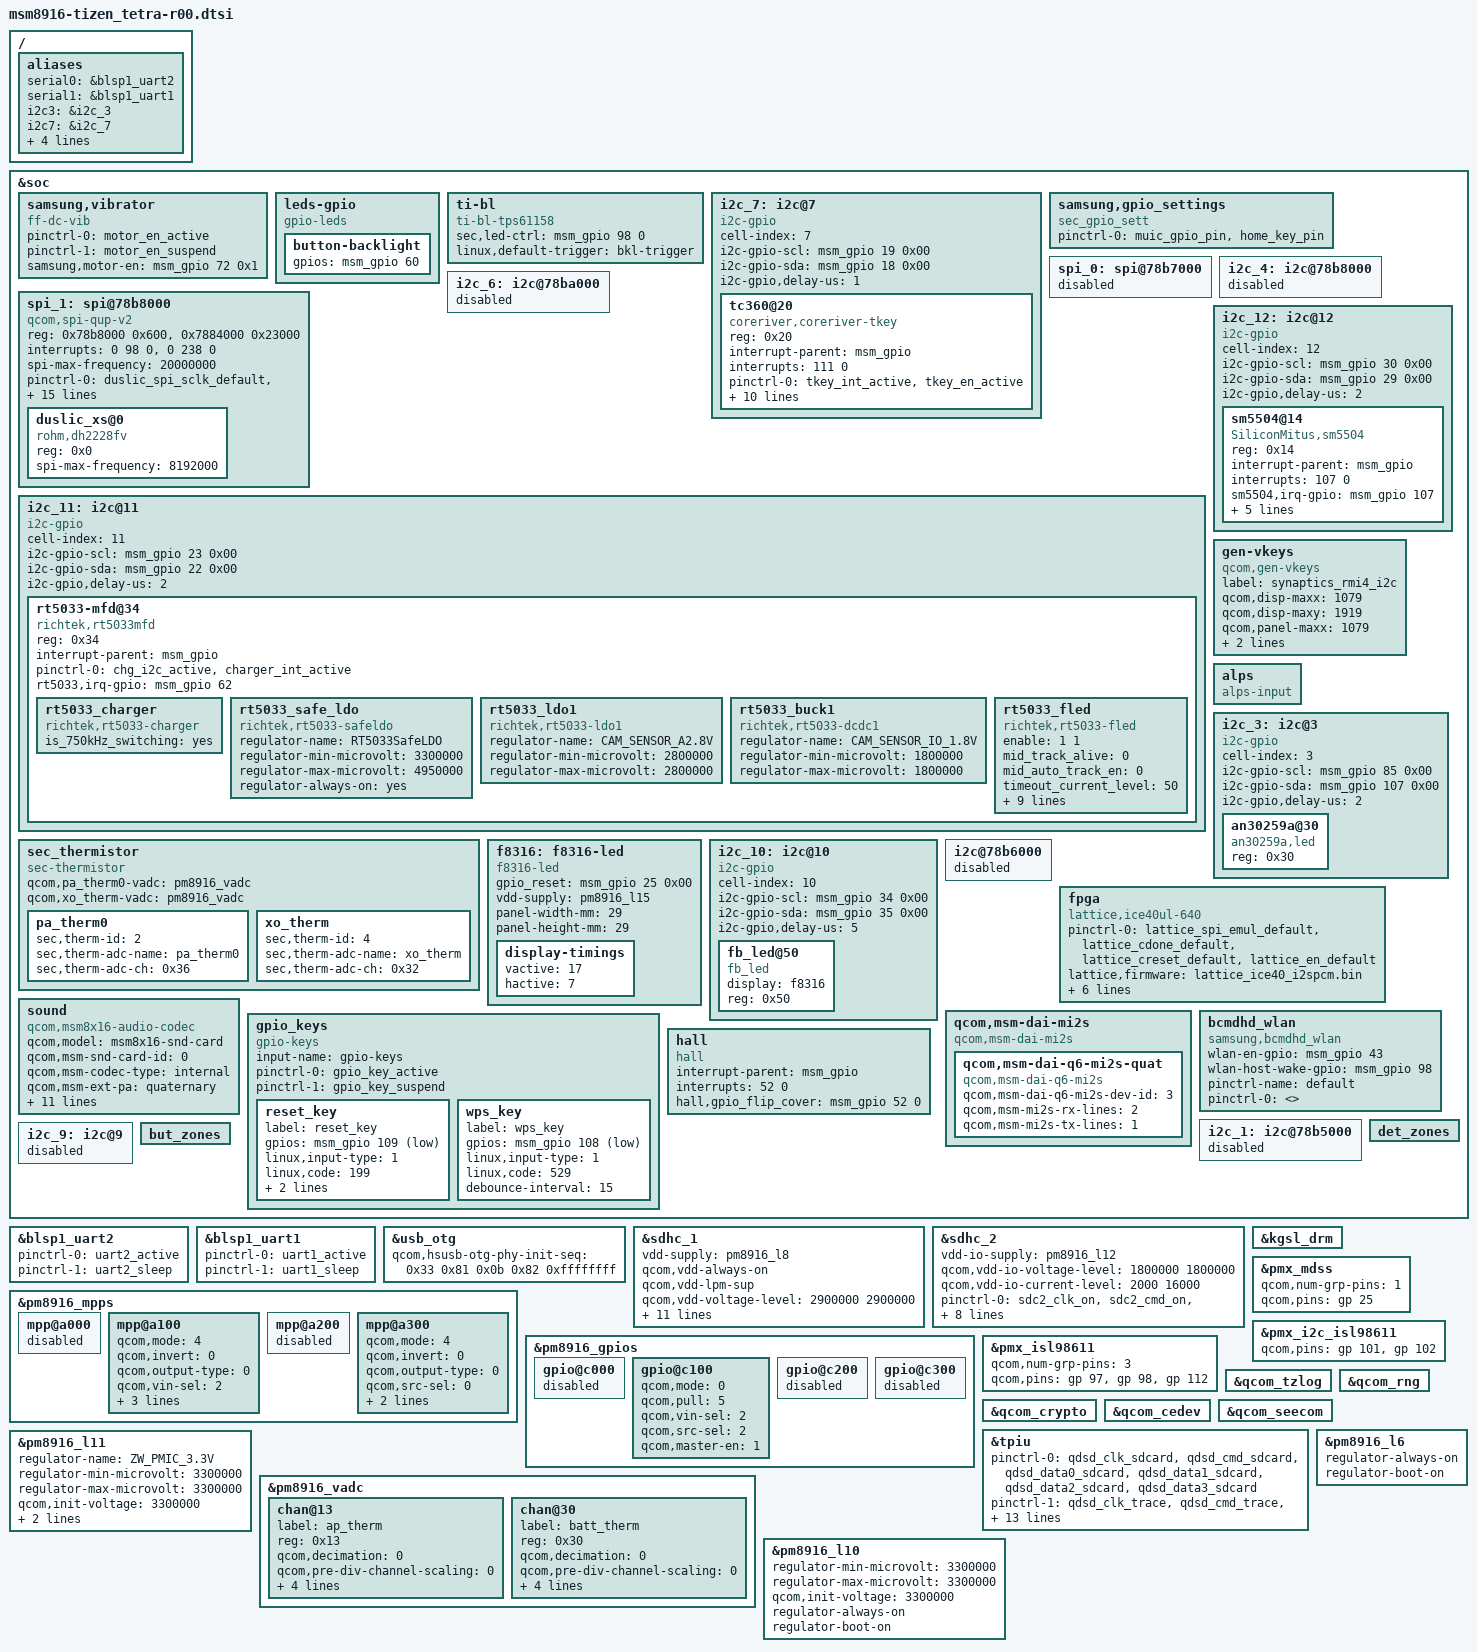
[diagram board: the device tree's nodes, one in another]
/* Copyright (c) 2014, The Linux Foundation. All rights reserved.
 *
 * This program is free software; you can redistribute it and/or modify
 * it under the terms of the GNU General Public License version 2 and
 * only version 2 as published by the Free Software Foundation.
 *
 * This program is distributed in the hope that it will be useful,
 * but WITHOUT ANY WARRANTY; without even the implied warranty of
 * MERCHANTABILITY or FITNESS FOR A PARTICULAR PURPOSE.  See the
 * GNU General Public License for more details.
 */

#include "msm8916.dtsi"
#include "msm8916-pinctrl-tizen-tetra-r00.dtsi"
#include "msm8916-w1-r01.dtsi"

/ {
	aliases {
		serial0 = &blsp1_uart2;
		serial1 = &blsp1_uart1;

		/*i2c-gpio bus_id*/
		i2c3 = &i2c_3;
		i2c7 = &i2c_7;
		i2c11 = &i2c_11;
		i2c12 = &i2c_12;
		i2c10 = &i2c_10;
		/*spi-gpio bus_id*/
		spi1 = &spi_1;
		};
};

&soc {
	samsung,vibrator {
		pinctrl-names = "tlmm_motor_en_active","tlmm_motor_en_suspend";
		pinctrl-0 = <&motor_en_active>;
		pinctrl-1 = <&motor_en_suspend>;
		compatible = "ff-dc-vib";
		samsung,motor-en = <&msm_gpio 72 0x1>;
		status = "ok";
	};

	leds-gpio{
		compatible = "gpio-leds";
		button-backlight{
			gpios = <&msm_gpio 60 0>;
			status = "ok";
		};
	};

	ti-bl {
		compatible = "ti-bl-tps61158";
		sec,led-ctrl = <&msm_gpio 98 0>;
		linux,default-trigger = "bkl-trigger";
	};

	i2c_7:i2c@7 {
                cell-index = <7>;
                compatible = "i2c-gpio";
                i2c-gpio-scl = <&msm_gpio 19  0x00>;
                i2c-gpio-sda = <&msm_gpio 18 0x00>;
                i2c-gpio,delay-us = <1>;
                #address-cells = <1>;
                #size-cells = <0>;

                tc360@20 {
                        compatible = "coreriver,coreriver-tkey";
                        reg = <0x20>;
                        interrupt-parent = <&msm_gpio>;
                        interrupts = <111 0>;
		pinctrl-names = "tkey_gpio_active","tkey_gpio_suspend";
		pinctrl-0 = <&tkey_int_active &tkey_en_active>;
		pinctrl-1 = <&tkey_int_suspend &tkey_en_suspend>;
                        coreriver,vcc_en-gpio = <&msm_gpio 60 0x00>;
                        coreriver,scl-gpio = <&msm_gpio 19 0x00>;
                        coreriver,sda-gpio = <&msm_gpio 18 0x00>;
                        coreriver,irq-gpio = <&msm_gpio  111 0x00>;
                        coreriver,keycodes = <169 158 529>;
                        coreriver,i2c-pull-up = <1>;
                        coreriver,gpio_seperated = <1>;
                        coreriver,fw-name = "tc350_tetra";
                        coreriver,firm-up;
                };
        };

	samsung,gpio_settings{
		compatible = "sec_gpio_sett";
		pinctrl-names = "sec_gpio_active","sec_gpio_suspend";
		pinctrl-0 = <&muic_gpio_pin &home_key_pin>;
	};

	spi_0: spi@78b7000 { /* BLSP1 QUP2 */
		status = "disable";
	};

	i2c_4: i2c@78b8000 { /* BLSP1 QUP4 */
		status = "disable";
	};

	spi_1: spi@78b8000 { /* BLSP1 QUP3 */
		compatible = "qcom,spi-qup-v2";
		#address-cells = <1>;
		#size-cells = <0>;
		reg-names = "spi_physical", "spi_bam_physical";
		reg = <0x78b8000 0x600>, <0x7884000 0x23000>;
		interrupt-names = "spi_irq", "spi_bam_irq";
		interrupts = <0 98 0>, <0 238 0>;
		spi-max-frequency = <20000000>;

		pinctrl-names = "default", "sleep";
		pinctrl-0 = <&duslic_spi_sclk_default &duslic_spi_mosi_default &duslic_spi_miso_default &duslic_spi_cs_default>;
		pinctrl-1 = <&duslic_spi_sclk_sleep &duslic_spi_mosi_sleep &duslic_spi_miso_sleep &duslic_spi_cs_sleep>;

		clock-names = "iface_clk", "core_clk";
		clocks = <&clock_gcc clk_gcc_blsp1_ahb_clk>, <&clock_gcc clk_gcc_blsp1_qup4_spi_apps_clk>;
		qcom,infinite-mode = <0>;
		qcom,use-bam;
		qcom,use-pinctrl;
		qcom,ver-reg-exists;
		qcom,bam-consumer-pipe-index = <10>;
		qcom,bam-producer-pipe-index = <11>;
		qcom,master-id = <86>;
		status = "ok";

		duslic_xs@0 {
		    compatible = "rohm,dh2228fv";
		    reg = <0x0>;
		    spi-max-frequency = <8192000>;
		};
	};

	i2c_6: i2c@78ba000 { /* BLSP1 QUP6 */
		status = "disable";
	};

       i2c_11:i2c@11 {
		cell-index = <11>;
		compatible = "i2c-gpio";
		i2c-gpio-scl = <&msm_gpio 23 0x00>;
		i2c-gpio-sda = <&msm_gpio 22 0x00>;
		i2c-gpio,delay-us = <2>;
		#address-cells = <1>;
		#size-cells = <0>;

		rt5033-mfd@34{
			compatible = "richtek,rt5033mfd";
			reg = <0x34>;
			interrupt-parent = <&msm_gpio>;
			pinctrl-names = "default";
			pinctrl-0 = <&chg_i2c_active &charger_int_active>;
			rt5033,irq-gpio = <&msm_gpio 62 0x00>;

			rt5033_charger {
				compatible = "richtek,rt5033-charger";
				is_750kHz_switching = "yes";
			};

			rt5033_safe_ldo {
				compatible = "richtek,rt5033-safeldo";
				regulator-name = "RT5033SafeLDO"; /* constraints->name, change name by yourself*/
				regulator-min-microvolt = <3300000>;
				regulator-max-microvolt = <4950000>; /* if max == min then apply_uV = 1 */
				regulator-always-on = "yes";
			};

			rt5033_ldo1 {
				compatible = "richtek,rt5033-ldo1";
				regulator-name = "CAM_SENSOR_A2.8V"; /* change name by yourself */
				regulator-min-microvolt = <2800000>;
				regulator-max-microvolt = <2800000>; /* max == min then apply_uV = 1 */
			};


			rt5033_buck1 {
				compatible = "richtek,rt5033-dcdc1";
				regulator-name = "CAM_SENSOR_IO_1.8V"; /* change name by yourself */
				regulator-min-microvolt = <1800000>;
				regulator-max-microvolt = <1800000>; /* max == min then apply_uV = 1 */
			};

			rt5033_fled {
				compatible = "richtek,rt5033-fled";
				enable = <1 1>;
				mid_track_alive = <0>;
				mid_auto_track_en = <0>;
				timeout_current_level = <50>;
				strobe_current = <500>;
				strobe_timeout = <544>;
				torch_current = <63>;
				lv_protection = <3000>;
				mid_level = <4400>;
				rt5033,led1-gpio = <&msm_gpio 34 0x00>;
				rt5033,led2-gpio = <&msm_gpio 36 0x00>;
				pinctrl-names = "fled_defualt","fled_sleep";
				pinctrl-0 = <&gpio_led_default>;
				pinctrl-1 = <&gpio_led_sleep>;
			};
		};
	};
	
    	i2c_12:i2c@12 {
       	cell-index = <12>;
		compatible = "i2c-gpio";
		i2c-gpio-scl = <&msm_gpio 30 0x00>;
		i2c-gpio-sda = <&msm_gpio 29 0x00>;
		i2c-gpio,delay-us = <2>;
		#address-cells = <1>;
		#size-cells = <0>;

		sm5504@14{
			compatible = "SiliconMitus,sm5504";
			reg = <0x14>;
			interrupt-parent = <&msm_gpio>;
			interrupts= <107 0>;
			sm5504,irq-gpio = <&msm_gpio 107 0x00>;
			sm5504,gpio-sda = <&msm_gpio 29 0x00>;
			sm5504,gpio-scl = <&msm_gpio 30 0x00>;
			sm5504,uarton-gpio = <&msm_gpio 114 0x00>;
			pinctrl-names = "sm5504_i2c_active","sm5504_i2c_suspend";
			pinctrl-0 = <&muic_i2c_active &muic_int_pin>;
			pinctrl-1 = <&muic_i2c_suspend &muic_int_pin>;
		};
	};
	
	gen-vkeys {
		compatible = "qcom,gen-vkeys";
		label = "synaptics_rmi4_i2c";
		qcom,disp-maxx = <1079>;
		qcom,disp-maxy = <1919>;
		qcom,panel-maxx = <1079>;
		qcom,panel-maxy = <2084>;
		qcom,key-codes = <158 139 172 217>;
	};

	sec_thermistor {
		compatible = "sec-thermistor";
		qcom,pa_therm0-vadc = <&pm8916_vadc>;
		qcom,xo_therm-vadc = <&pm8916_vadc>;
		pa_therm0 {
			sec,therm-id = <2>; /* SEC_THERM_PAM0 */
			sec,therm-adc-name = "pa_therm0";
			sec,therm-adc-ch = <0x36>;
		};
		xo_therm {
			sec,therm-id = <4>; /* SEC_THERM_XO */
			sec,therm-adc-name = "xo_therm";
			sec,therm-adc-ch = <0x32>;
		};
	};

	alps {
		compatible = "alps-input";
	};

	i2c_3: i2c@3 {
		cell-index = <3>;
		compatible = "i2c-gpio";
		i2c-gpio-scl = <&msm_gpio 85 0x00>;
		i2c-gpio-sda = <&msm_gpio 107 0x00>;
		i2c-gpio,delay-us = <2>;
		#address-cells = <1>;
		#size-cells = <0>;

		an30259a@30{
			compatible = "an30259a,led";
			reg = <0x30>;
		};
	};

	f8316: f8316-led {
		compatible = "f8316-led";
		gpio_reset = <&msm_gpio 25 0x00>;
		vdd-supply = <&pm8916_l15>;
		panel-width-mm = <29>;
		panel-height-mm = <29>;
		display-timings {
			vactive = <17>;
			hactive = <7>;
		};
	};

	i2c_10: i2c@10 {
		cell-index = <10>;
		compatible = "i2c-gpio";
		i2c-gpio-scl = <&msm_gpio 34 0x00>;
		i2c-gpio-sda = <&msm_gpio 35 0x00>;
		i2c-gpio,delay-us = <5>;
		#address-cells = <1>;
		#size-cells = <0>;
		fb_led@50{
			compatible = "fb_led";
			display = <&f8316>;
			reg = <0x50>;
		};
	};

	i2c@78b6000 { /* BLSP1 QUP2 */
		status = "disable";
	};

	fpga {
		compatible = "lattice,ice40ul-640";

		pinctrl-names = "default";
		pinctrl-0 = <&lattice_spi_emul_default &lattice_cdone_default
					&lattice_creset_default &lattice_en_default>;
		/*pinctrl-1 = <&lattice_spi_emul_sleep>;*/

		lattice,firmware = "lattice_ice40_i2spcm.bin";
		lattice,spi-sclk-gpio = <&msm_gpio 7 0>;
		lattice,spi-mosi-gpio = <&msm_gpio 6 0>;
		lattice,spi-cs-gpio = <&msm_gpio 24 0>;

		lattice,cdone-gpio = <&msm_gpio 20 0>;
		lattice,creset-gpio = <&msm_gpio 21 0>;

		lattice,fpga-en-gpio = <&msm_gpio 87 0>;
		status = "ok";
	};

	/* Over-riding model specific changes */
	sound {
		compatible = "qcom,msm8x16-audio-codec";
		qcom,model = "msm8x16-snd-card"; /*qcom,model = "msm8x16-snd-card-mtp";*/
		qcom,msm-snd-card-id = <0>;
		qcom,msm-codec-type = "internal";
		qcom,msm-ext-pa = "quaternary";
		qcom,audio-routing =
			"RX_BIAS", "MCLK",
			"SPK_RX_BIAS", "MCLK",
			"INT_LDO_H", "MCLK",
			"MIC BIAS External", "Handset Mic",
			"MIC BIAS External2", "Secondary Mic",
			"AMIC1", "MIC BIAS External",
			"AMIC2", "Headset Mic",
			"AMIC3", "MIC BIAS External2";
		pinctrl-names =
				"cdc_lines_act",
				"cdc_lines_sus",
				"cdc_lines_quat_ext_act",
				"cdc_lines_quat_ext_sus";
		pinctrl-0 = <&cdc_pdm_lines_act>;
		pinctrl-1 = <&cdc_pdm_lines_sus>;
		pinctrl-2 = <&cdc_pdm_lines_act &ext_cdc_tlmm_lines_act>;
		/*pinctrl-3 = <&cdc_pdm_lines_sus &ext_cdc_tlmm_lines_sus>;*/
		/* quat-mi2s always on */
		pinctrl-3 = <&cdc_pdm_lines_sus>;
	};

	qcom,msm-dai-mi2s {
		compatible = "qcom,msm-dai-mi2s";

		qcom,msm-dai-q6-mi2s-quat {
			compatible = "qcom,msm-dai-q6-mi2s";
			qcom,msm-dai-q6-mi2s-dev-id = <3>;
			/* SWAP D-IN, D-OUT */
			qcom,msm-mi2s-rx-lines = <2>;
			qcom,msm-mi2s-tx-lines = <1>;
		};
	};

	bcmdhd_wlan {
		compatible = "samsung,bcmdhd_wlan";
		wlan-en-gpio = <&msm_gpio 43 0>;
		wlan-host-wake-gpio = <&msm_gpio 98 0>;
		pinctrl-name = "default";
		pinctrl-0 = <>;
	};
};

&blsp1_uart2 {
	status = "ok";
	pinctrl-names = "default","sleep";
	pinctrl-0 = <&uart2_active>;
	pinctrl-1 = <&uart2_sleep>;
};

&blsp1_uart1 {
	status = "ok";
	pinctrl-names = "default","sleep";
	pinctrl-0 = <&uart1_active>;
	pinctrl-1 = <&uart1_sleep>;
};

&soc {
	gpio_keys {
		compatible = "gpio-keys";
		input-name = "gpio-keys";
		pinctrl-names = "tlmm_gpio_key_active","tlmm_gpio_key_suspend";
		pinctrl-0 = <&gpio_key_active>;
		pinctrl-1 = <&gpio_key_suspend>;

		reset_key {
			label = "reset_key";
			gpios = <&msm_gpio 109 0x1>;
			linux,input-type = <1>;
			linux,code = <199>;
			gpio-key,wakeup;
			debounce-interval = <15>;
		};
		wps_key {
			label = "wps_key";
			gpios = <&msm_gpio 108 0x1>;
			linux,input-type = <1>;
			linux,code = <529>;
			debounce-interval = <15>;
		};
	};

	hall {
		status = "okay";
		compatible = "hall";
		interrupt-parent = <&msm_gpio>;
		interrupts = <52 0>;
		hall,gpio_flip_cover = <&msm_gpio 52 0>;

	};

	i2c_1: i2c@78b5000 { /* BLSP1 QUP1 */
		status="disable";
	};

	i2c_9:i2c@9 { /*SM5502 GPIO-I2C*/
		status="disable";
	};

	det_zones: det_zones {
		#list-det-cells = <4>;
	};

	but_zones: but_zones {
		#list-but-cells = <3>;
	};
};

&usb_otg {
	qcom,hsusb-otg-phy-init-seq = <0x33 0x81 0x0b 0x82 0xffffffff>;
};

&sdhc_1 {
	vdd-supply = <&pm8916_l8>;
	qcom,vdd-always-on;
	qcom,vdd-lpm-sup;
	qcom,vdd-voltage-level = <2900000 2900000>;
	qcom,vdd-current-level = <200 400000>;

	vdd-io-supply = <&pm8916_l5>;
	qcom,vdd-io-always-on;
	qcom,vdd-io-lpm-sup;
	qcom,vdd-io-voltage-level = <1800000 1800000>;
	qcom,vdd-io-current-level = <200 60000>;

	pinctrl-names = "active", "sleep";
	pinctrl-0 = <&sdc1_clk_on &sdc1_cmd_on &sdc1_data_on>;
	pinctrl-1 = <&sdc1_clk_off &sdc1_cmd_off &sdc1_data_off>;

	qcom,nonremovable;

	status = "ok";
};

&sdhc_2 {
	vdd-io-supply = <&pm8916_l12>;
	qcom,vdd-io-voltage-level = <1800000 1800000>;
	qcom,vdd-io-current-level = <2000 16000>;

	pinctrl-names = "active", "sleep";
	pinctrl-0 = <&sdc2_clk_on &sdc2_cmd_on &sdc2_data_on>;
	pinctrl-1 = <&sdc2_clk_off &sdc2_cmd_off &sdc2_data_off>;

	#address-cells = <0>;
	interrupt-parent = <&sdhc_2>;
	interrupts = <0 1>;
	#interrupt-cells = <1>;
	interrupt-map-mask = <0xffffffff>;
	interrupt-map = <0 &intc 0 125 0
			1 &intc 0 221 0>;
	interrupt-names = "hc_irq", "pwr_irq";

	status-cb = <2>;
	status = "ok";
};

&pm8916_mpps {
	mpp@a000 { /* MPP 1 */
		/* VDD_PX */
		status = "disabled";
	};

	mpp@a100 { /* MPP 2 */
		status = "ok";
		qcom,mode = <4>; // AIN input
		qcom,invert = <0>; //No Invert
		qcom,output-type = <0>; //CMOS
		qcom,vin-sel = <2>; //PM8971_S3 1.8v
		qcom,src-sel = <0>; //MPP Constant
		qcom,ain-route = <1>; // QPNP_PIN_AIN_AMUX_CH6 = 1 for MPP2
		qcom,master-en = <1>; // Function constant
	};

	mpp@a200 { /* MPP 3 */
		/* VREF DAC */
		status = "disabled";
	};

	mpp@a300 { /* MPP 4 */
		status = "ok";
		qcom,mode = <4>; // AIN input
		qcom,invert = <0>; //No Invert
		qcom,output-type = <0>; //CMOS
		qcom,src-sel = <0>; //MPP Constant
		qcom,ain-route = <3>; // QPNP_PIN_AIN_AMUX_CH8 = 3 for MPP4
		qcom,master-en = <1>; // Function constant
	};
};

&pm8916_gpios {
	gpio@c000 { /* GPIO 1 */
		/* Battery UICC Alarm */
		status = "disabled";
	};

	gpio@c100 { /* GPIO 2 */
		/* NFC_CLK_REQ */
		qcom,mode = <0>; /* QPNP_PIN_MODE_DIG_IN */
		qcom,pull = <5>; /* QPNP_PIN_PULL_NO */
		qcom,vin-sel = <2>; /* QPNP_PIN_VIN2 */
		qcom,src-sel = <2>; /* QPNP_PIN_SEL_FUNC_1 */
		qcom,master-en = <1>;
	};

	gpio@c200 { /* GPIO 3 */
		/* External regulator control for WTR */
		status = "disabled";
	};

	gpio@c300 { /* GPIO 4 */
		/* External regulator control for APC */
		status = "disabled";
	};
};

&kgsl_drm {
	status="okay";
};

&pmx_mdss {
	qcom,num-grp-pins = <1>;
	qcom,pins = <&gp 25>;
};

&pmx_i2c_isl98611 {
	qcom,pins = <&gp 101>, <&gp 102>;
};

&pmx_isl98611 {
	qcom,num-grp-pins = <3>;
	qcom,pins = <&gp 97>, <&gp 98>, <&gp 112>;
};

&qcom_tzlog {
	status = "okay";
};

&qcom_rng {
	status = "okay";
};

&qcom_crypto {
	status = "okay";
};

&qcom_cedev {
	status = "okay";
};

&qcom_seecom {
	status = "okay";
};

/* CoreSight */
&tpiu {
	pinctrl-names = "sdcard", "trace", "swduart",
			"swdtrc", "jtag", "spmi";
	/* NIDnT */
	pinctrl-0 = <&qdsd_clk_sdcard &qdsd_cmd_sdcard
			&qdsd_data0_sdcard &qdsd_data1_sdcard
			&qdsd_data2_sdcard &qdsd_data3_sdcard>;
	pinctrl-1 = <&qdsd_clk_trace &qdsd_cmd_trace
			&qdsd_data0_trace &qdsd_data1_trace
			&qdsd_data2_trace &qdsd_data3_trace>;
	pinctrl-2 = <&qdsd_cmd_swduart &qdsd_data0_swduart
			&qdsd_data1_swduart &qdsd_data2_swduart
			&qdsd_data3_swduart>;
	pinctrl-3 = <&qdsd_clk_swdtrc &qdsd_cmd_swdtrc
			&qdsd_data0_swdtrc &qdsd_data1_swdtrc
			&qdsd_data2_swdtrc &qdsd_data3_swdtrc>;
	pinctrl-4 = <&qdsd_cmd_jtag &qdsd_data0_jtag
			&qdsd_data1_jtag &qdsd_data2_jtag
			&qdsd_data3_jtag>;
	pinctrl-5 = <&qdsd_clk_spmi &qdsd_cmd_spmi
			&qdsd_data0_spmi &qdsd_data3_spmi>;
};

&pm8916_l6 {
	regulator-always-on;
	regulator-boot-on;
};

&pm8916_l11 {
	regulator-name = "ZW_PMIC_3.3V";
	regulator-min-microvolt = <3300000>;
	regulator-max-microvolt = <3300000>;
	qcom,init-voltage = <3300000>;
	status = "okay";
	regulator-always-on;
	regulator-boot-on;
};

&pm8916_vadc {
	chan@13 {
		label = "ap_therm";
		reg = <0x13>; // channel 19 for MPP4 , 1:1scale
		qcom,decimation = <0>;
		qcom,pre-div-channel-scaling = <0>; // 1:1scale
		qcom,calibration-type = "ratiometric";
		qcom,scale-function = <1>;
		qcom,hw-settle-time = <2>;
		qcom,fast-avg-setup = <0>;
	};

	chan@30 {
		label = "batt_therm";
		reg = <0x30>; // LR_MUX1_BATT_THERM , 1:1scale
		qcom,decimation = <0>;
		qcom,pre-div-channel-scaling = <0>; // 1:1scale
		qcom,calibration-type = "ratiometric";
		qcom,scale-function = <1>;
		qcom,hw-settle-time = <2>;
		qcom,fast-avg-setup = <0>;
	};
};

&pm8916_l10 {
	regulator-min-microvolt = <3300000>;
	regulator-max-microvolt = <3300000>;
	qcom,init-voltage = <3300000>;
	status = "okay";
	regulator-always-on;
	regulator-boot-on;
};
